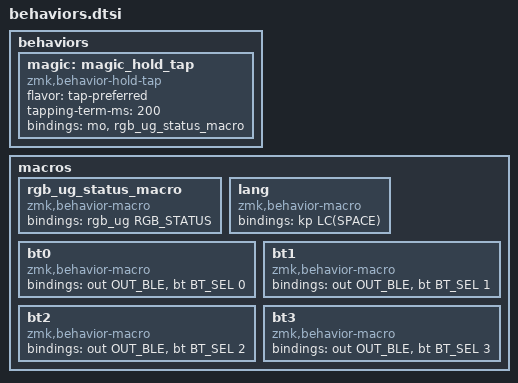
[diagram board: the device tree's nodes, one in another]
/* Behaviors referenced from config/layout.json. Plain ZMK, no custom module. */
behaviors {
    /* MoErgo's Magic key: hold for the Magic layer, tap for the RGB status display. */
    magic: magic_hold_tap {
        compatible = "zmk,behavior-hold-tap"; #binding-cells = <2>;
        flavor = "tap-preferred"; tapping-term-ms = <200>;
        bindings = <&mo>, <&rgb_ug_status_macro>;
    };
};
macros {
    rgb_ug_status_macro: rgb_ug_status_macro {
        compatible = "zmk,behavior-macro"; #binding-cells = <0>;
        bindings = <&rgb_ug RGB_STATUS>;
    };
    /* English/Russian: macOS "Select the previous input source". Both Shifts together are Caps Lock (combo in the keymap). */
    lang: lang { compatible = "zmk,behavior-macro"; #binding-cells = <0>; bindings = <&kp LC(SPACE)>; };
    bt0: bt0 { compatible = "zmk,behavior-macro"; #binding-cells = <0>; bindings = <&out OUT_BLE>, <&bt BT_SEL 0>; };
    bt1: bt1 { compatible = "zmk,behavior-macro"; #binding-cells = <0>; bindings = <&out OUT_BLE>, <&bt BT_SEL 1>; };
    bt2: bt2 { compatible = "zmk,behavior-macro"; #binding-cells = <0>; bindings = <&out OUT_BLE>, <&bt BT_SEL 2>; };
    bt3: bt3 { compatible = "zmk,behavior-macro"; #binding-cells = <0>; bindings = <&out OUT_BLE>, <&bt BT_SEL 3>; };
};
